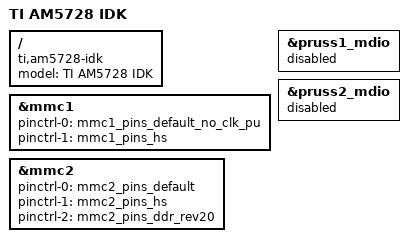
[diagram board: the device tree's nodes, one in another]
// SPDX-License-Identifier: GPL-2.0-only
/*
 * Copyright (C) 2015-2016 Texas Instruments Incorporated - https://www.ti.com/
 */

/dts-v1/;

#include "am5728.dtsi"
#include "dra7-mmc-iodelay.dtsi"
#include "dra74x-mmc-iodelay.dtsi"
#include "am572x-idk-common.dtsi"

/ {
	model = "TI AM5728 IDK";
	compatible = "ti,am5728-idk", "ti,am5728", "ti,dra7";
};

&mmc1 {
	pinctrl-names = "default", "hs";
	pinctrl-0 = <&mmc1_pins_default_no_clk_pu>;
	pinctrl-1 = <&mmc1_pins_hs>;
};

&mmc2 {
	pinctrl-names = "default", "hs", "ddr_3_3v";
	pinctrl-0 = <&mmc2_pins_default>;
	pinctrl-1 = <&mmc2_pins_hs>;
	pinctrl-2 = <&mmc2_pins_ddr_rev20>;
};

&pruss1_mdio {
	status = "disabled";
};

&pruss2_mdio {
	status = "disabled";
};
